# PIC16LF1719 register map
Vendor: Microchip
Architecture 16Exxx. Special function registers and configuration words.
Registers are 8-bit, read-write, reset 0x0 unless marked. A register's access mark holds for its fields unless they carry their own. Addresses are absolute, and some are shared; only a register's first bit layout is shown; lines under a group give offsets from that group; [hi:lo] are bit positions; {n}, {i} and the like mark numbered series; 'fields as' and 'values as' point back to an identical list; <NAME> marks a mode.

## Further device data
pins=1: RE3/MCLR; 2: RA0/AN0/C1IN0-/C2IN0-; 3: RA1/AN1/C1IN1-/C2IN1-/OPA1OUT; 4: RA2/AN2/Vref-/C1IN0+/C2IN0+/DAC1OUT1; 5: RA3/AN3/Vref+/C1IN1+; 6: RA4/OPA1IN+; 7: RA5/AN4/OPA1IN-/DAC2OUT1; 8: RE0/AN5; 9: RE1/AN6; 10: RE2/AN7; 11: Vdd; 12: Vss; 13: RA7/OSC1/CLKIN; 14: RA6/OSC2/CLKOUT; 15: RC0/SOSCO; 16: RC1/SOSCI; 17: RC2/AN14; 18: RC3/AN15; 19: RD0/AN20; 20: RD1/AN21; 21: RD2/AN22; 22: RD3/AN23; 23: RC4/AN16; 24: RC5/AN17; 25: RC6/AN18; 26: RC7/AN19; 27: RD4/AN24; 28: RD5/AN25; 29: RD6/AN26; 30: RD7/AN27; 31: Vss; 32: Vdd; 33: RB0/AN12/C2IN1+/ZCD; 34: RB1/AN10/C1IN3-/C2IN3-/OPA2OUT; 35: RB2/AN8/OPA2IN-; 36: RB3/AN9/C1IN2-/C2IN2-/OPA2IN+; 37: RB4/AN11; 38: RB5/AN13; 39: RB6/ICSPCLK; 40: RB7/DAC1OUT2/DAC2OUT2/ICSPDAT

## tmr
0x1A TMR2 — 8-bit period timer
0x1B PR2 reset 0xFF
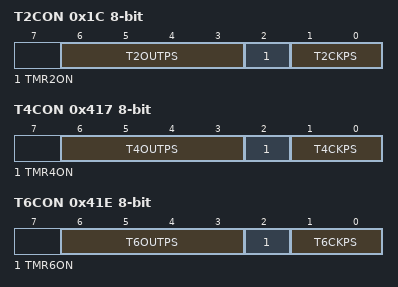
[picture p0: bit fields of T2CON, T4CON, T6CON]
0x1C T2CON
  [6:3] T2OUTPS, [2] TMR2ON, [1:0] T2CKPS
0x415 TMR4 — 8-bit period timer
0x416 PR4 reset 0xFF
0x417 T4CON
  [6:3] T4OUTPS, [2] TMR4ON, [1:0] T4CKPS
0x41C TMR6 — 8-bit period timer
0x41D PR6 reset 0xFF
0x41E T6CON
  [6:3] T6OUTPS, [2] TMR6ON, [1:0] T6CKPS

## cmp_rr
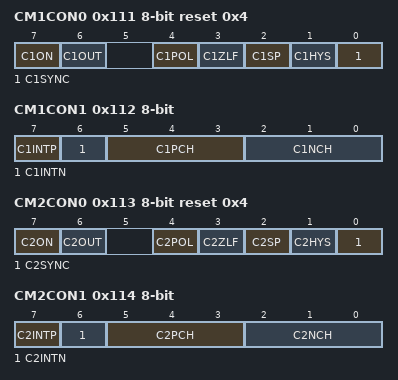
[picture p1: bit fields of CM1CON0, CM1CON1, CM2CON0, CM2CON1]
0x111 CM1CON0 reset 0x4
  [7] C1ON, [6] C1OUT ro, [4] C1POL, [3] C1ZLF, [2] C1SP, [1] C1HYS, [0] C1SYNC
0x112 CM1CON1
  [7] C1INTP, [6] C1INTN, [5:3] C1PCH, [2:0] C1NCH
0x113 CM2CON0 reset 0x4
  [7] C2ON, [6] C2OUT ro, [4] C2POL, [3] C2ZLF, [2] C2SP, [1] C2HYS, [0] C2SYNC
0x114 CM2CON1
  [7] C2INTP, [6] C2INTN, [5:3] C2PCH, [2:0] C2NCH

## 8bit_DAC
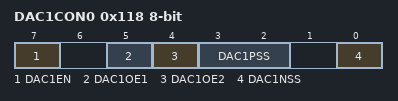
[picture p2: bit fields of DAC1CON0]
0x118 DAC1CON0
  [7] DAC1EN, [5] DAC1OE1, [4] DAC1OE2, [3:2] DAC1PSS, [0] DAC1NSS
0x119 DAC1CON1
  [7:0] DAC1R

## 5bit_DAC_wNSS
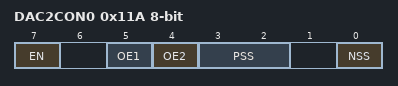
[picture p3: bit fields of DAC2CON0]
0x11A DAC2CON0
  [7] EN, [5] OE1, [4] OE2, [3:2] PSS, [0] NSS
0x11B DAC2REF
  [4:0] DACR

## cmp_zxover_ctrl
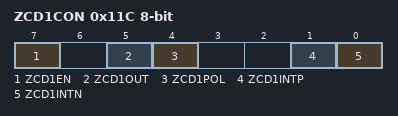
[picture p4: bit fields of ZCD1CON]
0x11C ZCD1CON reset not defined — (power-on value 0-x0--00)
  [7] ZCD1EN, [5] ZCD1OUT ro, [4] ZCD1POL, [1] ZCD1INTP, [0] ZCD1INTN

## mssp
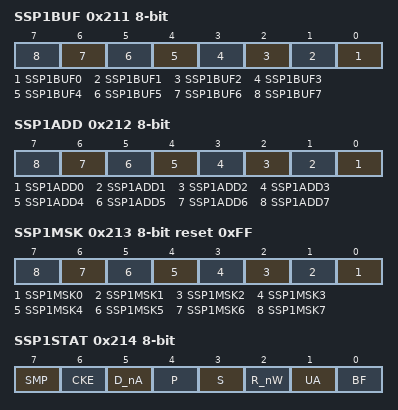
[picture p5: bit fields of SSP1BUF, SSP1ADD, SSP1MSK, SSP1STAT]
0x211 SSP1BUF reset not defined — (power-on value xxxxxxxx)
  [n] SSP1BUF{n} (n=0..7)
0x212 SSP1ADD
  [n] SSP1ADD{n} (n=0..7)
0x213 SSP1MSK reset 0xFF
  [n] SSP1MSK{n} (n=0..7)
0x214 SSP1STAT
  [7] SMP, [6] CKE, [5] D_nA ro, [4] P ro, [3] S ro, [2] R_nW ro, [1] UA ro, [0] BF ro
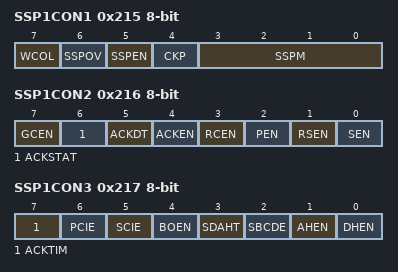
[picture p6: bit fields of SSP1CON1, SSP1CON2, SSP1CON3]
0x215 SSP1CON1
  [7] WCOL ro, [6] SSPOV ro, [5] SSPEN, [4] CKP, [3:0] SSPM
0x216 SSP1CON2
  [7] GCEN, [6] ACKSTAT ro, [5] ACKDT, [4] ACKEN, [3] RCEN, [2] PEN, [1] RSEN, [0] SEN
0x217 SSP1CON3
  [7] ACKTIM ro, [6] PCIE, [5] SCIE, [4] BOEN, [3] SDAHT, [2] SBCDE, [1] AHEN, [0] DHEN

## ccp
0x291 CCPR1L reset not defined — (power-on value xxxxxxxx)
0x292 CCPR1H reset not defined — (power-on value xxxxxxxx)
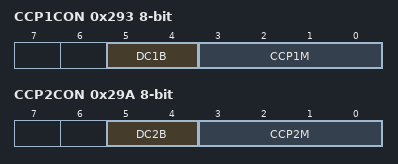
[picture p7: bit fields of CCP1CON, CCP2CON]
0x293 CCP1CON
  [5:4] DC1B, [3:0] CCP1M
0x298 CCPR2L reset not defined — (power-on value xxxxxxxx)
0x299 CCPR2H reset not defined — (power-on value xxxxxxxx)
0x29A CCP2CON
  [5:4] DC2B, [3:0] CCP2M

## DOS_01444B_NCO
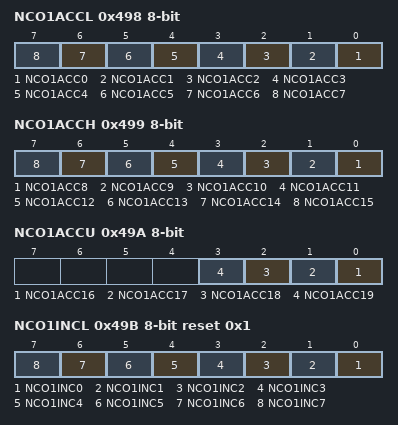
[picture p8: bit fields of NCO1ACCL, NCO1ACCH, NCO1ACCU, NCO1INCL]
0x498 NCO1ACCL
  [n] NCO1ACC{n} (n=0..7)
0x499 NCO1ACCH
  [n-8] NCO1ACC{n} (n=8..15)
0x49A NCO1ACCU
  [n-16] NCO1ACC{n} (n=16..19)
0x49B NCO1INCL reset 0x1
  [n] NCO1INC{n} (n=0..7)
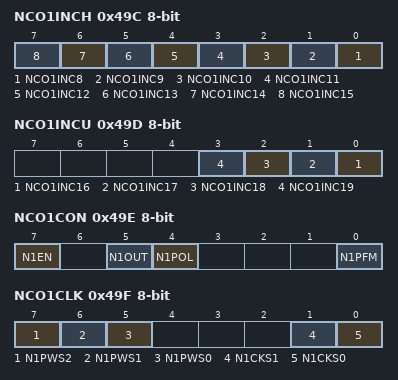
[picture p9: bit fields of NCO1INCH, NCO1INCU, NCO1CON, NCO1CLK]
0x49C NCO1INCH
  [n-8] NCO1INC{n} (n=8..15)
0x49D NCO1INCU
  [n-16] NCO1INC{n} (n=16..19)
0x49E NCO1CON — Configurable logic cell control
  [7] N1EN, [5] N1OUT ro, [4] N1POL, [0] N1PFM
0x49F NCO1CLK
  [7] N1PWS2, [6] N1PWS1, [5] N1PWS0, [1] N1CKS1, [0] N1CKS0
